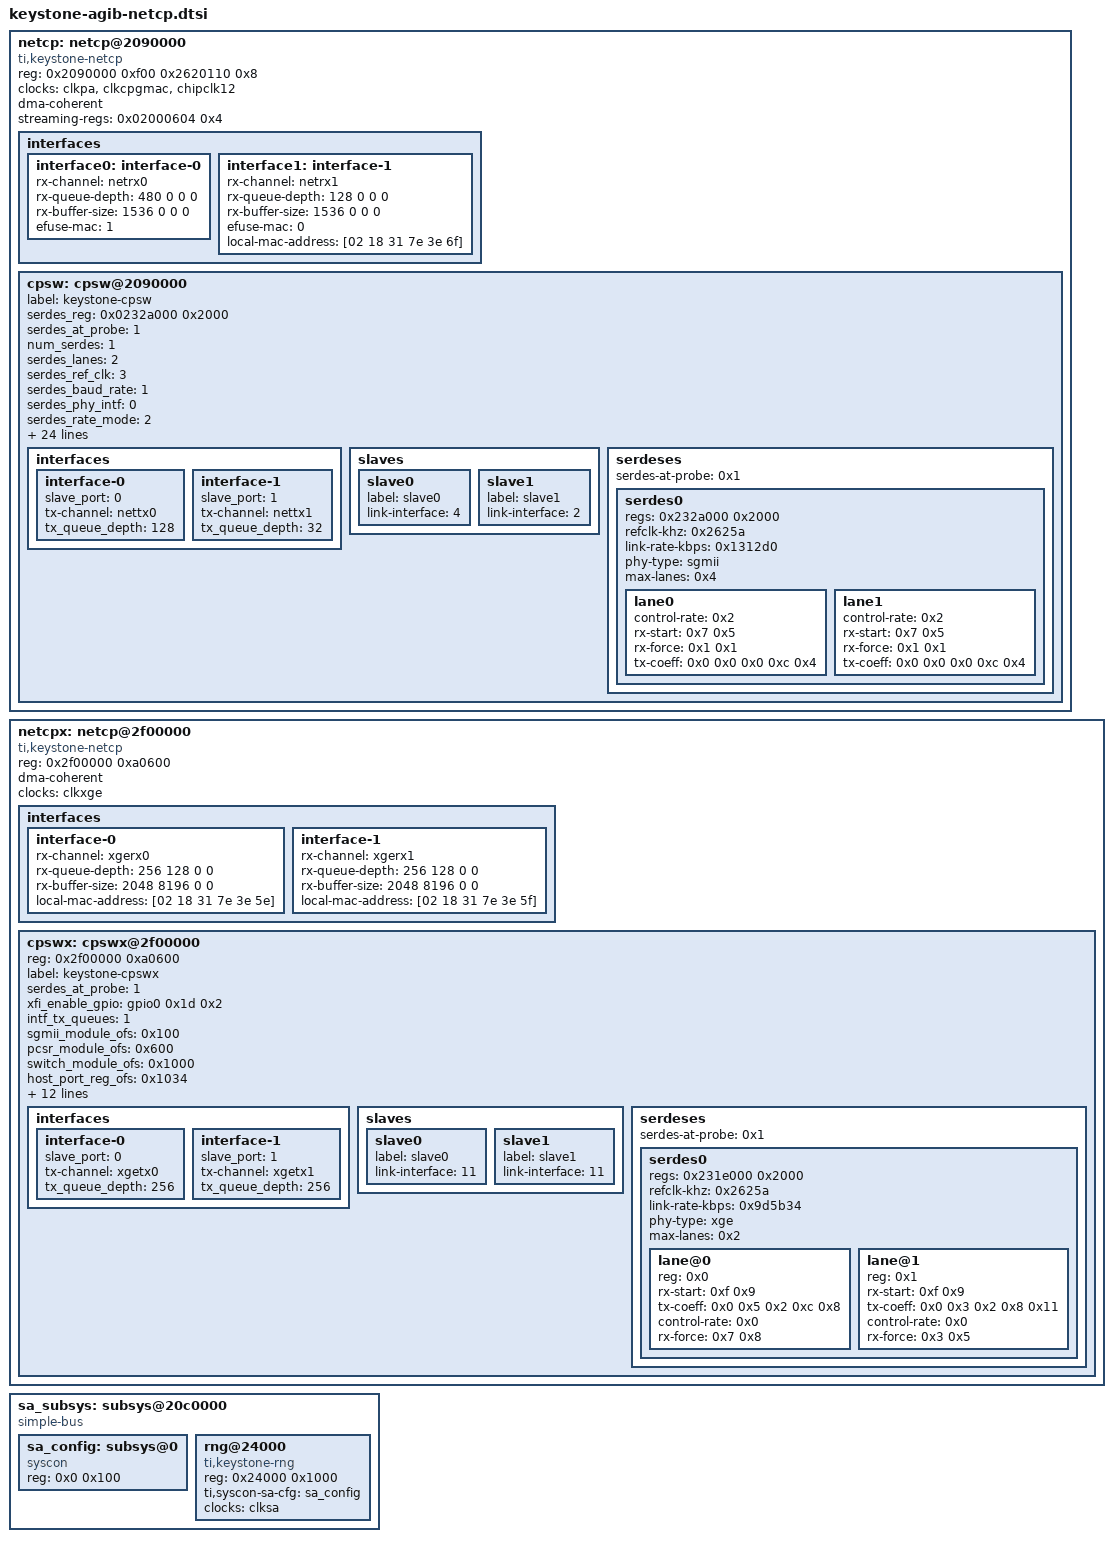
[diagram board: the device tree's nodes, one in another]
// SPDX-License-Identifier: GPL-2.0
/*
 * Device Tree Source for Keystone 2 Hawking Netcp driver
 *
 * Copyright (C) 2015-2017 Texas Instruments Incorporated - http://www.ti.com/
 */

netcp: netcp@2090000 {
	reg = <0x2090000 0xf00
		0x2620110 0x8>;
	compatible = "ti,keystone-netcp";

	/*clocks = <&papllclk>, <&clkcpgmac>, <&chipclk12>;*/
	clocks = <&clkpa>, <&clkcpgmac>, <&chipclk12>;
	clock-names = "clk_pa", "clk_cpgmac", "cpsw_cpts_rft_clk";
	/*clock-names = "pa_clk", "ethss_clk", "cpts";*/
	dma-coherent;
	streaming-regs = <0x02000604 0x4>;

	interfaces {
		interface0: interface-0 {
			rx-channel = "netrx0";
			rx-queue-depth = <480 0 0 0>;
			rx-buffer-size = <1536 0 0 0>;
			efuse-mac = <1>;
			/*local-mac-address = [02 18 31 7e 3e 6e]; */
		};
		interface1: interface-1 {
			rx-channel = "netrx1";
			rx-queue-depth = <128 0 0 0>;
			rx-buffer-size = <1536 0 0 0>;
			efuse-mac = <0>;
			local-mac-address = [02 18 31 7e 3e 6f];
		};
	};

	/* K2's ethernet switch configuration */
	cpsw: cpsw@2090000 {
		label = "keystone-cpsw";
		serdes_reg = <0x0232a000 0x2000>;
		serdes_at_probe		= <1>;
		num_serdes		= <1>;
		serdes_lanes		= <2>;
		serdes_ref_clk		= <3>; /* SERDES_CLOCK_156P25M */
		serdes_baud_rate	= <1>; /* SERDES_RATE_5G */
		serdes_phy_intf		= <0>; /* SERDES_PHY_SGMII */
		serdes_rate_mode	= <2>; /* SERDES_QUARTER_RATE */
		serdes_loopback		= <0>;

		intf_tx_queues = <7>;

		sgmii_module_ofs  = <0x100>;
		sgmii_module34_ofs  = <0x400>;
		switch_module_ofs = <0x800>;
		host_port_reg_ofs = <0x834>;
		slave_reg_ofs	  = <0x860>;
		sliver_reg_ofs	  = <0x900>;
		slave23_reg_ofs	  = <0xa00>;
		hw_stats_reg_ofs  = <0xb00>;
		cpts_reg_ofs	  = <0xd00>;
		ale_reg_ofs	  = <0xe00>;

		num_slaves  = <2>;
		ale_ageout  = <30>;
		ale_entries = <1024>;
		ale_ports   = <5>;

		cpts_rftclk_sel = <0>;
		/*cpts_rftclk_freq = <399360000>;*/
		cpts_ts_comp_length = <3>;
		cpts_clock_mult = <5000>;
		cpts_clock_shift = <10>;
		cpts_clock_div = <3>;
		/* force_no_hwtstamp; */

		multi-interface;
		num-interfaces = <2>;
		slaves-per-interface = <1>;

		interfaces {
			interface-0 {
				slave_port = <0>;
				tx-channel = "nettx0";
				tx_queue_depth = <128>;
			};
			interface-1 {
				slave_port = <1>;
				tx-channel = "nettx1";
				tx_queue_depth = <32>;
			};
		};

		slaves {
			slave0 {
				label		= "slave0";
				link-interface	= <4>;
			};
			slave1 {
				label		= "slave1";
				link-interface	= <2>;
			};
		};

		serdeses {
			serdes-at-probe = <0x1>;

			serdes0 {
				regs = <0x232a000 0x2000>;
				refclk-khz = <0x2625a>;
				link-rate-kbps = <0x1312d0>;
				phy-type = "sgmii";
				max-lanes = <0x4>;

				lane0 {
					control-rate = <0x2>;
					rx-start = <0x7 0x5>;
					rx-force = <0x1 0x1>;
					tx-coeff = <0x0 0x0 0x0 0xc 0x4>;
				};

				lane1 {
					control-rate = <0x2>;
					rx-start = <0x7 0x5>;
					rx-force = <0x1 0x1>;
					tx-coeff = <0x0 0x0 0x0 0xc 0x4>;
				};
			};
		};
	};
};

netcpx: netcp@2f00000 {
	#address-cells = <1>;
	#size-cells = <1>;
	reg = <0x2f00000 0xa0600>;
	compatible = "ti,keystone-netcp";
	dma-coherent;

	clocks = <&clkxge>;
	clock-names = "clk_xge";

	interfaces {
		interface-0 {
			rx-channel = "xgerx0";
			rx-queue-depth = <256 128 0 0>;
			/* BIP MTU is 2000B, interface MTU is 8174 */
			rx-buffer-size = <2048 8196 0 0>;
			local-mac-address = [02 18 31 7e 3e 5e]; /*+++FIXME*/
		};
		interface-1 {
			rx-channel = "xgerx1";
			rx-queue-depth = <256 128 0 0>;
			/* BIP MTU is 2000B, interface MTU is 8174 */
			rx-buffer-size = <2048 8196 0 0>;
			local-mac-address = [02 18 31 7e 3e 5f]; /*+++FIXME*/
		};
	};

	cpswx: cpswx@2f00000 {
		reg = <0x2f00000 0xa0600>;
		label = "keystone-cpswx";
		serdes_at_probe = <1>;
		xfi_enable_gpio = <&gpio0 0x1d 0x2>;

		intf_tx_queues = <1>;

		sgmii_module_ofs  = <0x100>;
		pcsr_module_ofs   = <0x600>;
		switch_module_ofs = <0x1000>;
		host_port_reg_ofs = <0x1034>;
		slave_reg_ofs	  = <0x1064>;
		sliver_reg_ofs	  = <0x1400>;
		hw_stats_reg_ofs  = <0x1800>;
		ale_reg_ofs	  = <0x1700>;

		host_port  = <0>;
		num_slaves  = <2>;
		ale_ageout  = <30>;
		ale_entries = <2048>;
		ale_ports   = <3>;

		multi-interface;
		num-interfaces = <2>;
		slaves-per-interface = <1>;

		interfaces {
			interface-0 {
				slave_port = <0>;
				tx-channel = "xgetx0";
				tx_queue_depth = <256>;
			};
			interface-1 {
				slave_port = <1>;
				tx-channel = "xgetx1";
				tx_queue_depth = <256>;
			};
		};

		slaves {
			slave0 {
				label		= "slave0";
				link-interface	= <11>;        /* 11 - XGMII_LINK_MAC_MAC_FORCED */
			};
			slave1 {
				label		= "slave1";
				link-interface	= <11>;        /* 11 - XGMII_LINK_MAC_MAC_FORCED */
			};
		};

		serdeses {
			serdes-at-probe = <0x1>;

			serdes0 {
				regs = <0x231e000 0x2000>;
				refclk-khz = <0x2625a>;
				link-rate-kbps = <0x9d5b34>;
				phy-type = "xge";
				max-lanes = <0x2>;
				/* debug; */

				/*rx-force-enable;*/
				#address-cells = <0x1>;
				#size-cells = <0x0>;

				lane@0 {
					status = "ok";
					reg = <0x0>;
					rx-start = <0xf 0x9>;
					tx-coeff = <0x0 0x5 0x2 0xc 0x8>;
					control-rate = <0x0>;
					rx-force = <0x7 0x8>;
				};

				lane@1 {
					status = "ok";
					reg = <0x1>;
					rx-start = <0xf 0x9>;
					tx-coeff = <0x0 0x3 0x2 0x8 0x11>;
					control-rate = <0x0>;
					rx-force = <0x3 0x5>;
				};
			};
		};
	};
};

sa_subsys: subsys@20c0000 {
	compatible = "simple-bus";
	#address-cells = <1>;
	#size-cells = <1>;
	ranges = <0 0x20c0000 0x40000>;

	sa_config: subsys@0 {
		compatible = "syscon";
		reg = <0x0 0x100>;
	};

	rng@24000 {
		compatible = "ti,keystone-rng";
		reg = <0x24000 0x1000>;
		ti,syscon-sa-cfg = <&sa_config>;
		clocks = <&clksa>;
		clock-names = "fck";
	};
};
